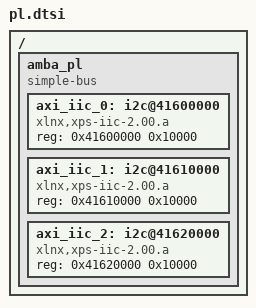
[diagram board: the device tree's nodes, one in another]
/*
 * CAUTION: This file is automatically generated by Xilinx.
 * Version:  
 * Today is: Wed Dec 02 13:59:28 2015
*/


/ {
	amba_pl: amba_pl {
		#address-cells = <1>;
		#size-cells = <1>;
		compatible = "simple-bus";
		ranges ;
		axi_iic_0: i2c@41600000 {
			#address-cells = <1>;
			#size-cells = <0>;
			compatible = "xlnx,xps-iic-2.00.a";
			reg = <0x41600000 0x10000>;
		};
		axi_iic_1: i2c@41610000 {
			#address-cells = <1>;
			#size-cells = <0>;
			compatible = "xlnx,xps-iic-2.00.a";
			reg = <0x41610000 0x10000>;
		};
		axi_iic_2: i2c@41620000 {
			#address-cells = <1>;
			#size-cells = <0>;
			compatible = "xlnx,xps-iic-2.00.a";
			reg = <0x41620000 0x10000>;
		};
	};
};
